# SF32LB55x register map
File version: 1.0
CPU: CM33 r0p1, little endian, MPU, FPU, 3 interrupt priority bits
Registers are 32-bit, read-write, reset 0x0 unless marked. A register's access mark holds for its fields unless they carry their own. Offsets are from the block's base; lines under a group give offsets from that group; [hi:lo] are bit positions; {n}, {i} and the like mark numbered series; 'fields as' and 'values as' point back to an identical list; <NAME> marks a mode.

## Memory map
0x40000000 HPSYS_RCC size 0x1000
0x40001000 DMAC1 size 0x1000
0x40003000 HPSYS_PINMUX1 size 0x1000
0x40004000 USART1 size 0x1000
0x40005000 USART2 size 0x1000
0x40006000 EZIP size 0x1000
0x40007000 EPIC size 0x1000
0x40008000 LCDC1 size 0x1000
0x40009000 I2S1 size 0x1000
0x4000A000 I2S2 size 0x1000
0x4000B000 HPSYS_CFG size 0x1000
0x4000C000 EFUSEC size 0x1000
0x4000D000 AES size 0x1000
0x4000E000 CRC size 0x1000
0x4000F000 TRNG size 0x1000
0x40010000 GPTIM1 size 0x1000
0x40011000 GPTIM2 size 0x1000
0x40012000 BTIM1 size 0x1000
0x40013000 BTIM2 size 0x1000
0x40014000 WDT1 size 0x1000
0x40015000 SPI1 size 0x1000
0x40016000 SPI2 size 0x1000
0x40017000 EXTDMA size 0x1000
0x4001A000 PDM1 size 0x1000
0x4001B000 PDM2 size 0x1000
0x4001C000 I2C1 size 0x1000
0x4001D000 I2C2 size 0x1000
0x4001E000 DSI_HOST size 0x1000
0x4001F000 DSI_PHY size 0x1000
0x40020000 PTC1 size 0x1000
0x40022000 I2C3 size 0x1000
0x40030000 HPSYS_AON size 0x1000
0x40031000 LPTIM1 size 0x1000
0x40040000 LPSYS_RCC size 0x1000
0x40041000 DMAC2 size 0x1000
0x40043000 LPSYS_PINMUX size 0x1000
0x40045000 USART3 size 0x1000
0x40046000 USART4 size 0x1000
0x40047000 USART5 size 0x1000
0x40049000 SPI3 size 0x1000
0x4004A000 SPI4 size 0x1000
0x4004C000 I2C4 size 0x1000
0x4004D000 I2C5 size 0x1000
0x4004E000 I2C6 size 0x1000
0x4004F000 LPSYS_CFG size 0x1000
0x40050000 GPTIM3 size 0x1000
0x40051000 GPTIM4 size 0x1000
0x40052000 GPTIM5 size 0x1000
0x40053000 BTIM3 size 0x1000
0x40054000 BTIM4 size 0x1000
0x40055000 WDT2 size 0x1000
0x40056000 GPADC size 0x1000
0x40057000 SDADC size 0x1000
0x4005A000 TSEN size 0x1000
0x4005B000 PTC2 size 0x1000
0x4005C000 LCDC2 size 0x1000
0x40070000 LPSYS_AON size 0x1000
0x40071000 LPTIM2 size 0x1000
0x40072000 LPTIM3 size 0x1000
0x4007A000 PMUC size 0x1000
0x4007C000 IWDT size 0x1000
0x50000000 HPSYS_GPIO size 0x1000
0x50004000 SDMMC1 size 0x1000
0x50005000 SDMMC2 size 0x1000
0x50040000 LPSYS_GPIO size 0x1000

## HPSYS_PINMUX1
Base 0x40003000
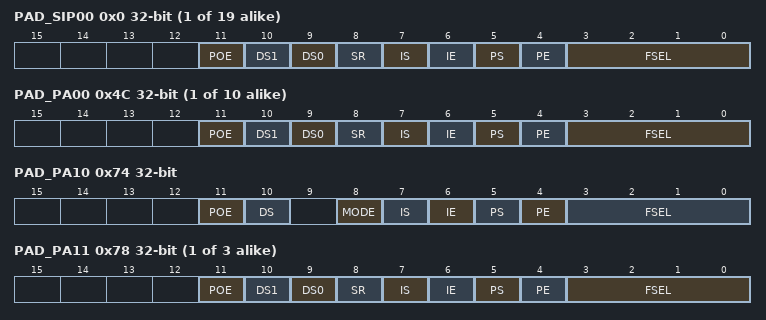
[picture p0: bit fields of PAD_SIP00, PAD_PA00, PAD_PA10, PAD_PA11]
{0x0+4i} PAD_SIP{i:02} (i=0..18)
  [11] POE — Parametric output enable. Logic LOW forces PO HIGH.
  [10] DS1 — Drive select 1. Used to select output drive strength.
  [9] DS0 — Drive select 0. Used to select output drive strength.
  [8] SR — Slew rate. Logic HIGH selects slow slew rate, logic LOW selects fast slew rate.
  [7] IS — Input select. Logic LOW selects CMOS input, and logic HIGH selects Schmitt input.
  [6] IE — Input enable. Logic HIGH enables the input buffer.
  [5] PS — Pull select. Logic HIGH selects pull-up, logic LOW selected pull-down.
  [4] PE — Pull enable. Logic HIGH enables weak pull device.
  [3:0] FSEL — Function Select
{0x4C+4i} PAD_PA{i:02} (i=0..9)
  fields as PAD_SIP00
0x74 PAD_PA10
  [11] POE — Parametric output enable. Logic LOW forces PO HIGH.
  [10] DS — Drive select. Logic LOW selects 4mA drive, logic HIGH selects 20mA drive.
  [8] MODE — Mode select. Logic LOW enables GPIO mode, logic HIGH enables I2C mode.
  [7] IS — Input select. Logic LOW selects CMOS input, and logic HIGH selects Schmitt input.
  [6] IE — Input enable. Logic HIGH enables the input buffer.
  [5] PS — Pull select. Logic HIGH selects pull-up, logic LOW selected pull-down.
  [4] PE — Pull enable. Logic HIGH enables weak pull device.
  [3:0] FSEL — Function Select
{0x4C+4i} PAD_PA{i} (i=11..13)
  fields as PAD_SIP00
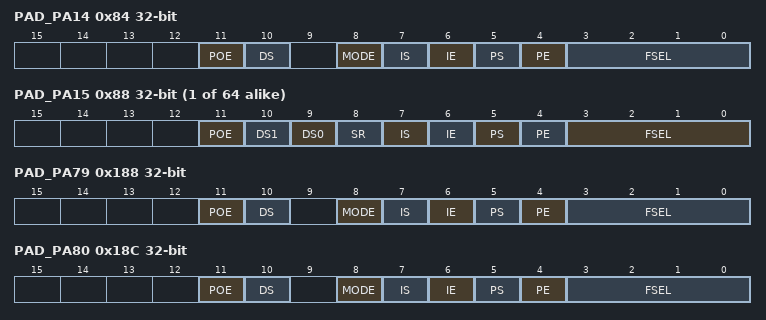
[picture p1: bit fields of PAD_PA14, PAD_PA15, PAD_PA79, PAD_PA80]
0x84 PAD_PA14
  fields as PAD_PA10
{0x4C+4i} PAD_PA{i} (i=15..78)
  fields as PAD_SIP00
0x188 PAD_PA79
  fields as PAD_PA10
0x18C PAD_PA80
  fields as PAD_PA10

## EZIP
Base 0x40006000
0x00 EZIP_CTRL — ezip decoder ctrl
  [0] EZIP_CTRL — 1:start and run 0:end
0x04 SRC_ADDR — ezip decoder source address
0x08 DST_ADDR — ezip decoder destination address
  [31:0] DST_ADDR — ezip decoder destination address(ahb_out mode)
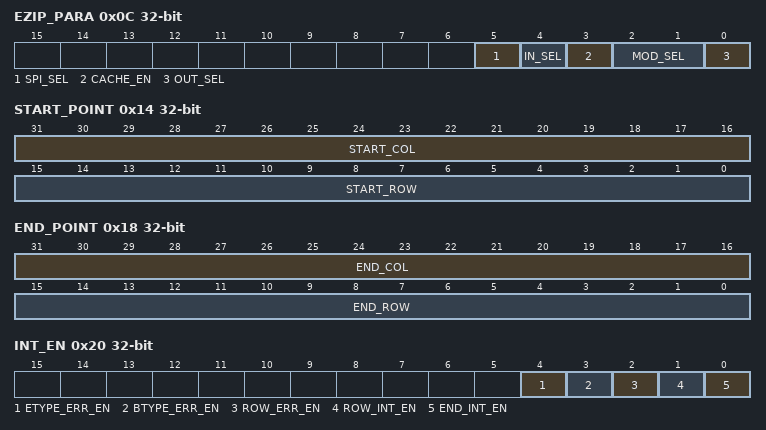
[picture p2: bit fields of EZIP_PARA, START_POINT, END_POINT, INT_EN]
0x0C EZIP_PARA — ezip decoder parameter
  [5] SPI_SEL — 0:QSPI3 1:QSPI2
  [4] IN_SEL — don't support ezip type2 ype4. 0:ahb 1:fifo
  [3] CACHE_EN — ezip index cache enable(only support ezip_type=4) 0:disable 1:enable
  [2:1] MOD_SEL — 0:ezip 1:gzip 2:Lz4
  [0] OUT_SEL — only used in ezip decoder mode. must select ahb in gzip/lz4 decoder mode. 0:epic 1:ahb
0x10 CACHE_CLR — ezd index cache clear
  [0] CACHE_CLR
0x14 START_POINT — ezip decoder start point
  [31:16] START_COL — ezd start col,count from 0
  [15:0] START_ROW — ezd start row,count from 0
0x18 END_POINT — ezip decoder end point
  [31:16] END_COL — ezd end col
  [15:0] END_ROW — ezd end row
0x1C ROW_SIGN — ezip decoder row sign
  [15:0] ROW_SIGN — arrived row sign,ezd can generate a interrupt
0x20 INT_EN — ezip decoder _int_en
  [4] ETYPE_ERR_EN — ezip_type_err_en
  [3] BTYPE_ERR_EN
  [2] ROW_ERR_EN
  [1] ROW_INT_EN
  [0] END_INT_EN — ezd_end _int_en
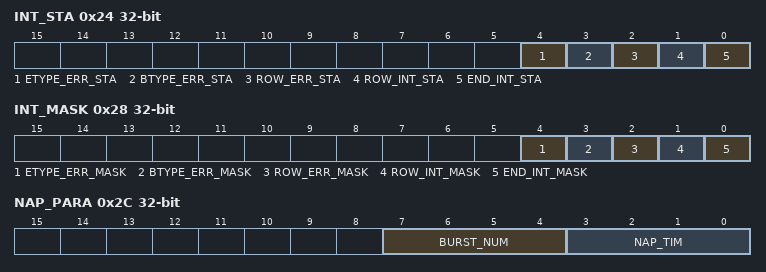
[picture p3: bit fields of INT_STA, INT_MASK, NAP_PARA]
0x24 INT_STA — ezip decoder _int_sta
  [4] ETYPE_ERR_STA — ezip_type_err_sta
  [3] BTYPE_ERR_STA
  [2] ROW_ERR_STA — overflow height sta
  [1] ROW_INT_STA — arrive row sign sta
  [0] END_INT_STA — ezd_end _int_sta
0x28 INT_MASK — ezip decoder int mask state
  [4] ETYPE_ERR_MASK — ezip_type_err_mask sta
  [3] BTYPE_ERR_MASK — btype_err_mask sta
  [2] ROW_ERR_MASK — overflow height mask sta
  [1] ROW_INT_MASK — arrive row sign mask sta
  [0] END_INT_MASK — ezd_end _int mask sta
0x2C NAP_PARA — ezip decoder release bus parameter
  [7:4] BURST_NUM — ezip decoder burst number 0000: 16 0001: 32 0010: 64 0100: 128 1000: 256 other: 16
  [3:0] NAP_TIM — ezip decoder release bus time 0000: not nap 0001: 16 cycle 0010: 32 cycle 0100: 64 cycle 1000: 128 cycle other: not nap
0x30 DB_SEL — ezip decoder debug sel
  [15:0] DB_SEL — bit[15] 0:line_first 1:out_buf_en[1] bit[14] 0:rd_head3 1:out_buf_en[0] bit[13] 0:rd_head2 1:inbuf_empty bit[12] 0:rd_heas1 1:inbuf_half_empty bit[11] 0:blk_restart 1: inbuf_full bit[10] 0:ezd_buf_end 1:ezd_pixel_end bit[9] 0:ezd_buf_full 1:0 bit[8] 0:ezd_buf_empty 1:0 bit[7] 0:dec_buf_empty 1:0 bit[6] 0:dec_buf_full 1:para_ok bit[5] 0:dec_on 1:ezd_fuf_push bit[4] 0:ind3_on 1:copy_on bit[3] 0:ind2_on 1:bypass_on bit[2] 0:ind1_on 1:blk_clr bit[1] 0:ezd_on 1:para_val bit[0] 0:ezd_int 1:para_req
0x34 DB_DATA0 — ezip decoder debug data0
  [31:0] DB_DATA0 — bit[31:24] bit_depth bit[23:16] color_type bit[15:0] block number
0x38 DB_DATA1 — ezip decoder debug data1
  [31:0] DB_DATA1 — bit[31:16] width bit[15:0] height
0x3C DB_DATA2 — ezip decoder debug data2
  [31:0] DB_DATA2 — bit[31:0] total_len
0x40 DB_DATA3 — ezip decoder debug data3
  [31:0] DB_DATA3 — bit[31:24] ezip_type bit[23:20] bfinal bit[19:16] btype bit[11:8] ahb_state bit[7:4] ctrl_state bir[3:0] build_stste
0x44 DB_DATA4 — ezip decoder debug data4
  [31:0] DB_DATA4 — bit[9]:ezd_buf_full bit[8]:ezd_buf_empty bit[7]:dec_buf_full bit[6]:dec_buf_empty bit[5]:bypass_on bit[4]:dec_on bit[3]:ind3_on bit[2]:ind2_on bit[1]:ind1_on bit[0]:ezd_on
0x48 DB_DATA5 — ezip decoder debug data5
  [31:0] DB_DATA5 — bit[31:16] width_cur bit[15:0] height_cur
0x4C SRC_LEN — ezip source data length
  [31:0] SRC_LEN — source data length only in source data fifo mode
